# DDRSS0_CTL_CFG register map
Vendor: Texas Instruments
Registers are 32-bit, read-write, reset 0x0 unless marked. A register's access mark holds for its fields unless they carry their own. Offsets are as the file gives them; [hi:lo] are bit positions; lines under a group give offsets from that group.

## DDRSS0_CTL_CFG (part 2 of 5)
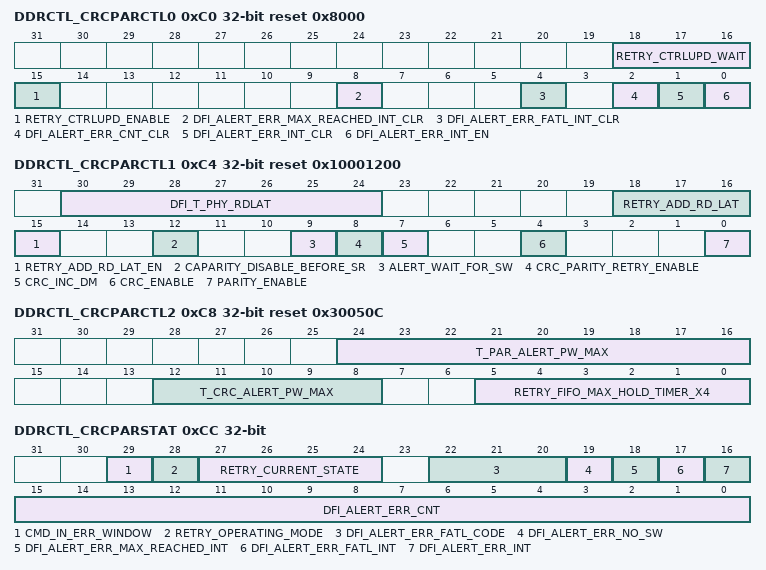
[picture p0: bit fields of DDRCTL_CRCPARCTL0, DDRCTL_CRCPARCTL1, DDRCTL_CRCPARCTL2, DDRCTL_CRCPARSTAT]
0xC0 DDRCTL_CRCPARCTL0 access not given reset 0x8000 — CRC Parity Control Register0
  [18:16] RETRY_CTRLUPD_WAIT rw — Additional wait time after dfi_ctrlupd_req for retry has occurred to ensure PHY's internals (FIFO pointers) have been reset correctly.Value used is 2^retry_ctrlupd_wait. Only used if DDRCTL_CRCPARCTL0.retry_ctrlupd_enable is enabled. Programming Mode: Static
  [15] RETRY_CTRLUPD_ENABLE rw — dfi_ctrlupd_req enable for retry.- 1: Enable to issue dfi_ctrlupd_req before starting retry sequence - 0: Disable to issue dfi_ctrlupd_req before starting retry sequence The DFI controller update can be used to reset PHY FIFO pointers. If both DDRCTL_CRCPARCTL0.retry_cfrlupd_enable and DDRCTL_CRCPARCTL1.alert_wait_for_sw are enabled, dfi_ctrlupd_req is issued just before software intervention time. If DDRCTL_CRCPARCTL0.retry_cfrlupd_enable is enabled, dfi_ctrlupd_req will be issued regardless of DDRCTL_DFIUPD0.dis_auto_ctrlupd. Programming Mode: Static
  [8] DFI_ALERT_ERR_MAX_REACHED_INT_CLR — Interrupt clear bit for DFI alert counter saturation.If this bit is set, the alert error interrupt on DDRCTL_CRCPARSTAT.dfi_alert_err_max_reached_int is cleared. When the clear operation is complete, the uMCTL2 automatically clears this bit. Programming Mode: Dynamic (access RW1C)
  [4] DFI_ALERT_ERR_FATL_INT_CLR — Interrupt clear bit for dfi_alert_err_fatl_int.If this bit is set, the alert error interrupt on DDRCTL_CRCPARSTAT.dfi_alert_err_fatl_int is cleared. When the clear operation is complete, the uMCTL2 automatically clears this bit. Programming Mode: Dynamic (access RW1C)
  [2] DFI_ALERT_ERR_CNT_CLR — DFI alert error count clear.Clear bit for DFI alert error counter. Asserting this bit will clear the DFI alert error counter, DDRCTL_CRCPARSTAT.dfi_alert_err_cnt. When the clear operation is complete, the uMCTL2 automatically clears this bit. Programming Mode: Dynamic (access RW1C)
  [1] DFI_ALERT_ERR_INT_CLR — Interrupt clear bit for DFI alert error.If this bit is set, the alert error interrupt on DDRCTL_CRCPARSTAT.dfi_alert_err_int will be cleared. When the clear operation is complete, the uMCTL2 automatically clears this bit. Programming Mode: Dynamic (access RW1C)
  [0] DFI_ALERT_ERR_INT_EN rw — Interrupt enable bit for DFI alert error.If this bit is set, any parity/CRC error detected on the dfi_alert_n input will result in an interrupt being set on DDRCTL_CRCPARSTAT.dfi_alert_err_int. Programming Mode: Dynamic
0xC4 DDRCTL_CRCPARCTL1 reset 0x10001200 — CRC Parity Control Register1
  [30:24] DFI_T_PHY_RDLAT — The maximum time allowed from the assertion of the dfi_rddata_en signal to the assertion of each of the corresponding bits of the dfi_rddata_valid signal.This corresponds to the DFI timing parameter tphy_rdlat. Refer to PHY specification for correct value. This value it only used for detecting read data timeout when DDR4 retry is enabled by DDRCTL_CRCPARCTL1.crc_parity_retry_enable=1. When the controller is operating in 1:2 frequency ratio mode, program this to the DFI timing parameter tphy_rdlat/2, and round it up to the next integer value. Unit: DFI clock cycles. Programming Mode: Static
  [18:16] RETRY_ADD_RD_LAT — Retry additional read latency value.Delay value used is retry_add_rd_lat+1. Only used if DDRCTL_CRCPARCTL1.retry_add_rd_lat_en is enabled. Selects the number of pipeline stages to dfi_rddata_valid/dfi_rddata/dfi_rddata_dbi before rest of internal uMCTL2 logic observes it. Required to compensate for fact delay in PHY/PCB for generating dfi_alert_n for retry may be more than the delay in PHY/PCB on read data path. Recommended settings (in terms of core_ddrc_core_clk): (Maximum Alert delay through PHY/PCB from erroneous read command including tPAR_UNKNOWN) - (Minimum Read data delay through PHY/PCB from erroneous read command) + (PHY's max granularity of dfi_rddata beats that may be corrupted before erroneous Read) Note: This calculation depends on various items such as RL, tPAR_ALERT_ON/tPAR_UNKNOWN/RCD/PHY/PCB behavior. Unit: DFI clock cycles. Programming Mode: Static
  [15] RETRY_ADD_RD_LAT_EN — Retry additional read latency enable.Number of pipeline stages selected is defined as DDRCTL_CRCPARCTL1.retry_add_lat+1. Only set if DDRCTL_CRCPARCTL1.crc_parity_retry_enable = 1 Programming Mode: Static
  [12] CAPARITY_DISABLE_BEFORE_SR — If DDR4-SDRAM's CA parity is enabled by DDRCTL_INIT6.mr5[2:0]!=0 and this register is set to 1, CA parity is automatically disabled before Self-Refresh entry and enabled after Self-Refresh exit by issuing MR5. - 1: CA parity is disabled before Self-Refresh entry - 0: CA parity is not disabled before Self-Refresh entry If Geardown is used by DDRCTL_MSTR.geardown_mode=1, this register must be set to 1. If this register set to 0, DDRCTL_DRAMTMG5.t_ckesr and DDRCTL_DRAMTMG5.t_cksre must be increased by PL(Parity latency) Programming Mode: Static
  [9] ALERT_WAIT_FOR_SW — After a Parity or CRC error is flagged on dfi_alert_n signal, the software has an option to read the mode registers in the DRAM before the hardware begins the retry process -1: Wait for software to read/write the mode registers before hardware begins the retry. After software is done with its operations, it will clear the alert interrupt register bit - 0: Hardware can begin the retry right away after the dfi_alert_n pulse goes away. The value on this register is valid only when retry is enabled (CRCPARCTRL.crc_parity_retry_enable = 1) If this register is set to 1 and if the software doesn't clear the interrupt register after handling the parity/CRC error, then the hardware will not begin the retry process and the system will hang. In the case of Parity/CRC error, there are two possibilities when the software doesn't reset MR5[4] to 0. - (i) If 'Persistent parity' mode register bit is NOT set: the commands sent during retry and normal operation are executed without parity checking. The value in the Parity error log register MPR Page 1 is valid. - (ii) If 'Persistent parity' mode register bit is SET: Parity checking is done for commands sent during retry and normal operation. If multiple errors occur before MR5[4] is cleared, the error log in MPR Page 1 should be treated as 'Don't care'. Programming Mode: Static
  [8] CRC_PARITY_RETRY_ENABLE — -1: Enable command retry mechanism in case of C/A Parity or CRC error - 0: Disable command retry mechanism when C/A Parity or CRC features are enabled. Note that retry functionality is not supported if burst chop is enabled (DDRCTL_MSTR.burstchop = 1) and/or disable auto-refresh is enabled (DDRCTL_RFSHCTL3.dis_auto_refresh = 1) Programming Mode: Static
  [7] CRC_INC_DM — CRC Calculation setting register -1: CRC includes DM signal - 0: CRC not includes DM signal Present only in designs configured to support DDR4. Programming Mode: Static
  [4] CRC_ENABLE — CRC enable Register -1: Enable generation of CRC - 0: Disable generation of CRC The setting of this register should match the CRC mode register setting in the DRAM. Programming Mode: Static
  [0] PARITY_ENABLE — C/A Parity enable register -1: Enable generation of C/A parity and detection of C/A parity error - 0: Disable generation of C/A parity and disable detection of C/A parity error If RCD's parity error detection or SDRAM's parity detection is enabled, this register should be 1. Programming Mode: Static
0xC8 DDRCTL_CRCPARCTL2 reset 0x30050C — CRC Parity Control Register2
  [24:16] T_PAR_ALERT_PW_MAX — Value from the DRAM spec indicating the maximum width of the dfi_alert_n pulse when a parity error occurs.Recommended values: - tPAR_ALERT_PW.MAX When the controller is operating in 1:2 frequency ratio mode, program this to tPAR_ALERT_PW.MAX/2 and round up to next integer value. Values of 0, 1 and 2 are illegal. This value must be greater than DDRCTL_CRCPARCTL2.t_crc_alert_pw_max. Programming Mode: Static
  [12:8] T_CRC_ALERT_PW_MAX — Value from the DRAM spec indicating the maximum width of the dfi_alert_n pulse when a CRC error occurs.Recommended values: - tCRC_ALERT_PW.MAX When the controller is operating in 1:2 frequency ratio mode, program this to tCRC_ALERT_PW.MAX/2 and round up to next integer value. Values of 0, 1 and 2 are illegal. This value must be less than DDRCTL_CRCPARCTL2.t_par_alert_pw_max. Programming Mode: Static
  [5:0] RETRY_FIFO_MAX_HOLD_TIMER_X4 — Indicates the maximum duration in number of DRAM clock cycles for which a command should be held in the Command Retry FIFO before it is popped out.Every location in the Command Retry FIFO has an associated down counting timer that will use this register as the start value. The down counting starts when a command is loaded into the FIFO. The timer counts down every 4 DRAM cycles. When the counter reaches zero, the entry is popped from the FIFO. All the counters are frozen, if a C/A Parity or CRC error occurs before the counter reaches zero. The counter is reset to 0, after all the commands in the FIFO are retried. Recommended(minimum) values: - Only C/A Parity is enabled. RoundUp((PHY Command Latency(DRAM CLK) + CAL + RCD delay + tPAR_ALERT_ON.max + tPAR_UNKNOWN + PHY Alert Latency(DRAM CLK) + board delay + PHY's max granularity of dfi_rddata beats that may be corrupted before erroneous Read) / 4) + 2 - Only CRC is enabled. RoundUp((PHY Command Latency(DRAM CLK) + CAL + RCD delay + WL + 5(BL10)+ tCRC_ALERT.max + PHY Alert Latency(DRAM CLK) + board delay) / 4) + 2 - If both C/A Parity and CRC are enabled. Use max of (Only C/A Parity is enabled, Only CRC is enabled) Note 1: All value (e.g. tPAR_ALERT_ON) should be in terms of DRAM Clock and round up Note 2: Board delay(Command/Alert_n) should be considered. Note 3: Use the worst case(longer) value for PHY Latencies/Board delay Note 4: The Recommended values are minimum value to be set. Note 5: RCD delay above refers to RDIMMs and LRDIMMs. Note 6: PHY's max granularity of dfi_rddata beats that may be corrupted before erroneous Read is depends on the internal architecture of the PHY. Max value can be set to this register is defined below: - MEMC_BURST_LENGTH == 16 Full bus Mode (CRC=OFF) Max value = UMCTL2_RETRY_CMD_FIFO_DEPTH - 2 Full bus Mode (CRC=ON) Max value = UMCTL2_RETRY_CMD_FIFO_DEPTH - 3 Half bus Mode (CRC=OFF) Max value = UMCTL2_RETRY_CMD_FIFO_DEPTH - 4 Half bus Mode (CRC=ON) Max value = UMCTL2_RETRY_CMD_FIFO_DEPTH - 6 Quarter bus Mode (CRC=OFF) Max value = UMCTL2_RETRY_CMD_FIFO_DEPTH - 8 Quarter bus Mode (CRC=ON) Max value = UMCTL2_RETRY_CMD_FIFO_DEPTH - 12 - MEMC_BURST_LENGTH != 16 Full bus Mode (CRC=OFF) Max value = UMCTL2_RETRY_CMD_FIFO_DEPTH - 1 Full bus Mode (CRC=ON) Max value = UMCTL2_RETRY_CMD_FIFO_DEPTH - 2 Half bus Mode (CRC=OFF) Max value = UMCTL2_RETRY_CMD_FIFO_DEPTH - 2 Half bus Mode (CRC=ON) Max value = UMCTL2_RETRY_CMD_FIFO_DEPTH - 3 Quarter bus Mode (CRC=OFF) Max value = UMCTL2_RETRY_CMD_FIFO_DEPTH - 4 Quarter bus Mode (CRC=ON) Max value = UMCTL2_RETRY_CMD_FIFO_DEPTH - 6 Values of 0, 1 and 2 are illegal. Programming Mode: Static
0xCC DDRCTL_CRCPARSTAT ro — CRC Parity Status Register
  [29] CMD_IN_ERR_WINDOW — Indicate if commands are in the parity/crc error window.- 0 - No command is in the parity/crc error window. - 1 - One or more commands are in the parity/crc error window or retry is in progress. This register is valid when CRCPARCTRL1.crc_parity_retry_enable=1. Programming Mode: Static
  [28] RETRY_OPERATING_MODE — Operating mode of retry -0 - Normal - 1 - Retry due to CRC/Parity error is in progress Programming Mode: Static
  [27:24] RETRY_CURRENT_STATE — Indicate current retry state for debug purposes only -0000 - IDLE:Retry is not enabled - 0001 - MON_DFI:Retry is enabled and monitoring DFI - 0010 - DETECTED ALERT:Detected dfi_alert_n - 0011 - WAKE_UP:Waking up from self-refresh state - 0100 - PRECHRGING:Pre-charging banks - 0101 - SEND_REF1:Sending extra REFs before software intervention time - 0110 - CTRLUPD:Issuing control update from retry logic - 0111 - WAIT_SW:Software intervention time - 1000 - SEND_REF2:Sending extra REFs before retrying commands - 1001 - RETRY_COMMANDS:Retrying commands - 1010 - RESTART_RETRY:Restarting retry due to alert_n detection during retry - 1111 - FATL_ERR:Fatal error detected FOR DEBUG PURPOSE ONLY Programming Mode: Static
  [22:20] DFI_ALERT_ERR_FATL_CODE — Indicate reason of dfi_alert_err_fatl_int assertion - [22] MPSMX caused parity error.(RCD's parity error detection only) - [21] Parity error happens again during software intervention time - [20] MRS was in retry_fifo_max_hold_timer_x4 window from alert_n=0 or DDRCTL_STAT.operating_mode is Init. Two or more reason can be available at the same time It remains set until cleared by DDRCTL_CRCPARCTL0.dfi_alert_err_fatl_clr. Programming Mode: Static
  [19] DFI_ALERT_ERR_NO_SW — Indicate whether software can perform MRS/MPR/PDA during software intervention time.- 0 - MRS/MPR/PDA can be performed during software intervention time - 1 - MRS/MPR/PDA can NOT be performed during software intervention time If DDRCTL_CRCPARCTL1.alert_wait_for_sw=1 and dfi_alert_err_no_sw=1, software can not perform MRS/MPR/PDA until dfi_alert_err_int is cleared by dfi_alert_err_int_clr. It remains set until cleared by DDRCTL_CRCPARCTL0.dfi_alert_err_int_clr. Programming Mode: Static
  [18] DFI_ALERT_ERR_MAX_REACHED_INT — DFI alert error counter max reached interrupt.If the DDRCTL_CRCPARSTAT.dfi_alert_err_cnt reaches it maximum value, this interrupt bit is set. It remains set until cleared by DDRCTL_CRCPARCTL0.dfi_alert_err_int_clr Programming Mode: Static
  [17] DFI_ALERT_ERR_FATL_INT — Fatal parity error interrupt.One or more these situation below happens, this interrupt bit is set. - MPSMX caused parity error. (RCD's parity error detection only) - Parity error happens again during software intervention time - MRS was in retry_fifo_max_hold_timer_x4 window from alert_n=0 or DDRCTL_STAT.operating_mode is Init. It remains set until cleared by DDRCTL_CRCPARCTL0.dfi_alert_err_fatl_clr. If this interrupt is asserted, system reset is strongly recommended. Programming Mode: Static
  [16] DFI_ALERT_ERR_INT — DFI alert error interrupt.If a parity/CRC error is detected on dfi_alert_n, and the interrupt is enabled by DDRCTL_CRCPARCTL0.dfi_alert_err_int_en, this interrupt bit will be set. It will remain set until cleared by DDRCTL_CRCPARCTL0.dfi_alert_err_int_clr Programming Mode: Static
  [15:0] DFI_ALERT_ERR_CNT — DFI alert error count.If a parity/CRC error is detected on dfi_alert_n, this counter be incremented. This is independent of the setting of DDRCTL_CRCPARCTL0.dfi_alert_err_int_en. It will saturate at 0xFFFF, and can be cleared by asserting DDRCTL_CRCPARCTL0.dfi_alert_err_cnt_clr. Programming Mode: Static
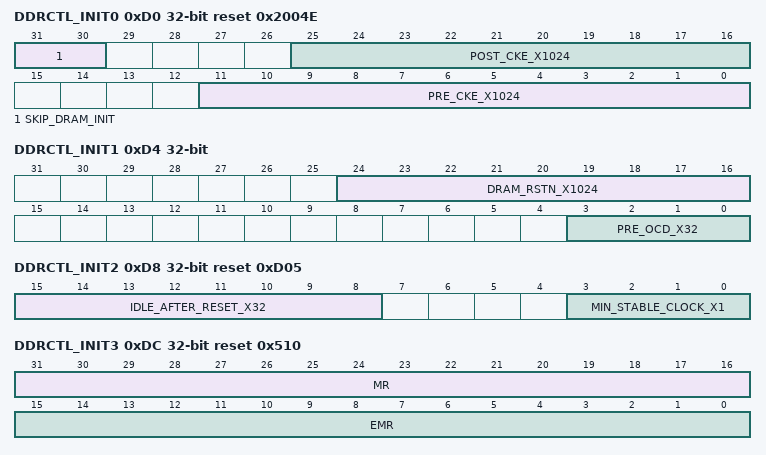
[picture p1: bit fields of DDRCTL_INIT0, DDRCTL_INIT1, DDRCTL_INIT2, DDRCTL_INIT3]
0xD0 DDRCTL_INIT0 reset 0x2004E — SDRAM Initialization Register 0
  [31:30] SKIP_DRAM_INIT — If lower bit is enabled the SDRAM initialization routine is skipped.The upper bit decides what state the controller starts up in when reset is removed - 00 - SDRAM Intialization routine is run after power-up - 01 - SDRAM Intialization routine is skipped after power-up. Controller starts up in Normal Mode - 11 - SDRAM Intialization routine is skipped after power-up. Controller starts up in Self-refresh Mode - 10 - SDRAM Intialization routine is run after power-up. Programming Mode: Quasi-dynamic Group 2
  [25:16] POST_CKE_X1024 — Cycles to wait after driving CKE high to start the SDRAM initialization sequence.Unit: 1024 DFI clock cycles. DDR2 typically requires a 400 ns delay, requiring this value to be programmed to 2 at all clock speeds. LPDDR2/LPDDR3 typically requires this to be programmed for a delay of 200 us. LPDDR4 typically requires this to be programmed for a delay of 2 us. When the controller is operating in 1:2 frequency ratio mode, program this to JEDEC spec value divided by 2, and round it up to the next integer value. Programming Mode: Static
  [11:0] PRE_CKE_X1024 — Cycles to wait after reset before driving CKE high to start the SDRAM initialization sequence.Unit: 1024 DFI clock cycles. DDR2 specifications typically require this to be programmed for a delay of &gt;= 200 us. LPDDR2/LPDDR3: tINIT1 of 100 ns (min) LPDDR4: tINIT3 of 2 ms (min) When the controller is operating in 1:2 frequency ratio mode, program this to JEDEC spec value divided by 2, and round it up to the next integer value. For DDR3/DDR4 RDIMMs, this should include the time needed to satisfy tSTAB Programming Mode: Static
0xD4 DDRCTL_INIT1 — SDRAM Initialization Register 1
  [24:16] DRAM_RSTN_X1024 — Number of cycles to assert SDRAM reset signal during init sequence.This is only present for designs supporting DDR3, DDR4 or LPDDR4 devices. For use with a DDR PHY, this should be set to a minimum of 1. When the controller is operating in 1:2 frequency ratio mode, program this to JEDEC spec value divided by 2, and round it up to the next integer value. Unit: 1024 DFI clock cycles. Programming Mode: Static
  [3:0] PRE_OCD_X32 — Wait period before driving the OCD complete command to SDRAM.Unit: Counts of a global timer that pulses every 32 DFI clock cycles. There is no known specific requirement for this it may be set to zero. Programming Mode: Static
0xD8 DDRCTL_INIT2 reset 0xD05 — SDRAM Initialization Register 2
  [15:8] IDLE_AFTER_RESET_X32 — Idle time after the reset command, tINIT4.Present only in designs configured to support LPDDR2. When the controller is operating in 1:2 frequency ratio mode, program this to JEDEC spec value divided by 2, and round it up to the next integer value. Unit: 32 DFI clock cycles. Programming Mode: Static
  [3:0] MIN_STABLE_CLOCK_X1 — Time to wait after the first CKE high, tINIT2.Present only in designs configured to support LPDDR2/LPDDR3. LPDDR2/LPDDR3 typically requires 5 x tCK delay. When the controller is operating in 1:2 frequency ratio mode, program this to JEDEC spec value divided by 2, and round it up to the next integer value. Unit: DFI clock cycles. Programming Mode: Static
0xDC DDRCTL_INIT3 reset 0x510 — SDRAM Initialization Register 3
  [31:16] MR — DDR2: Value to write to MR register. Bit 8 is for DLL and the setting here is ignored. The uMCTL2 sets this bit appropriately. DDR3/DDR4: Value loaded into MR0 register. mDDR: Value to write to MR register. LPDDR2/LPDDR3/LPDDR4 - Value to write to MR1 register Programming Mode: Quasi-dynamic Group 1 and Group 4
  [15:0] EMR — DDR2: Value to write to EMR register. Bits 9:7 are for OCD and the setting in this register is ignored. The uMCTL2 sets those bits appropriately. DDR3/DDR4: Value to write to MR1 register Set bit 7 to 0. If PHY-evaluation mode training is enabled, this bit is set appropriately by the uMCTL2 during write leveling. mDDR: Value to write to EMR register. LPDDR2/LPDDR3/LPDDR4 - Value to write to MR2 register Programming Mode: Quasi-dynamic Group 4
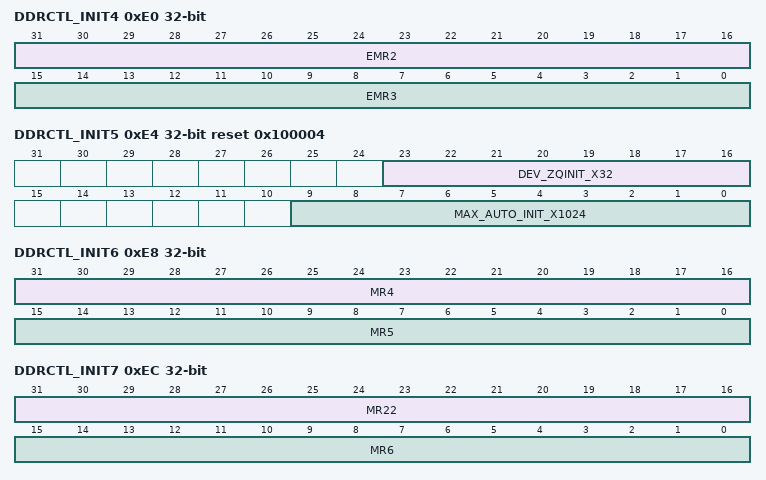
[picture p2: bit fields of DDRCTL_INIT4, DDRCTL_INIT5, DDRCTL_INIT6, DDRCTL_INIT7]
0xE0 DDRCTL_INIT4 — SDRAM Initialization Register 4
  [31:16] EMR2 — DDR2: Value to write to EMR2 register. DDR3/DDR4: Value to write to MR2 register LPDDR2/LPDDR3/LPDDR4: Value to write to MR3 register mDDR: Unused Programming Mode: Quasi-dynamic Group 4
  [15:0] EMR3 — DDR2: Value to write to EMR3 register. DDR3/DDR4: Value to write to MR3 register mDDR/LPDDR2/LPDDR3: Unused LPDDR4: Value to write to MR13 register Programming Mode: Quasi-dynamic Group 2 and Group 4
0xE4 DDRCTL_INIT5 reset 0x100004 — SDRAM Initialization Register 5
  [23:16] DEV_ZQINIT_X32 — ZQ initial calibration, tZQINIT.Present only in designs configured to support DDR3 or DDR4 or LPDDR2/LPDDR3. DDR3 typically requires 512 SDRAM clock cycles. DDR4 requires 1024 SDRAM clock cycles. LPDDR2/LPDDR3 requires 1 us. When the controller is operating in 1:2 frequency ratio mode, program this to JEDEC spec value divided by 2, and round it up to the next integer value. Unit: 32 DFI clock cycles. Programming Mode: Static
  [9:0] MAX_AUTO_INIT_X1024 — Maximum duration of the auto initialization, tINIT5.Present only in designs configured to support LPDDR2/LPDDR3. LPDDR2/LPDDR3 typically requires 10 us. Unit: 1024 DFI clock cycles. Programming Mode: Static
0xE8 DDRCTL_INIT6 — SDRAM Initialization Register 6
  [31:16] MR4 — DDR4- Value to be loaded into SDRAM MR4 registers. LPDDR4- Value to be loaded into SDRAM MR11 registers. Programming Mode: Quasi-dynamic Group 2 and Group 4
  [15:0] MR5 — DDR4- Value to be loaded into SDRAM MR5 registers. LPDDR4- Value to be loaded into SDRAM MR12 registers. Programming Mode: Quasi-dynamic Group 1 and Group 4
0xEC DDRCTL_INIT7 — SDRAM Initialization Register 7
  [31:16] MR22 — LPDDR4- Value to be loaded into SDRAM MR22 registers. Used in LPDDR4 designs only. Programming Mode: Quasi-dynamic Group 4
  [15:0] MR6 — DDR4- Value to be loaded into SDRAM MR6 registers. LPDDR4- Value to be loaded into SDRAM MR14 registers. Programming Mode: Quasi-dynamic Group 4
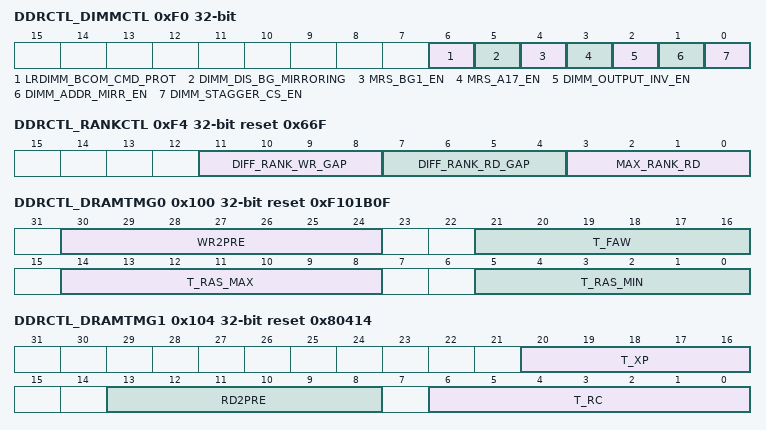
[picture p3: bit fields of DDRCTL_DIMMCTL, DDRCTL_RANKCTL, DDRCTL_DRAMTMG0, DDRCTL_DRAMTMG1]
0xF0 DDRCTL_DIMMCTL — DIMM Control Register
  [6] LRDIMM_BCOM_CMD_PROT — Protects the timing restrictions (tBCW/tMRC) between consecutive BCOM commands defined in the Data Buffer specification.When using DDR4 LRDIMM, this bit must be set to 1. Otherwise, this bit must be set to 0. Programming Mode: Static
  [5] DIMM_DIS_BG_MIRRORING — Disabling Address Mirroring for BG bits.When this is set to 1, BG0 and BG1 are NOT swapped even if Address Mirroring is enabled. This will be required for DDR4 DIMMs with x16 devices. - 1 - BG0 and BG1 are NOT swapped. - 0 - BG0 and BG1 are swapped if address mirroring is enabled. Programming Mode: Static
  [4] MRS_BG1_EN — Enable for BG1 bit of MRS command.BG1 bit of the mode register address is specified as RFU (Reserved for Future Use) and must be programmed to 0 during MRS. In case where DRAMs which do not have BG1 are attached and both the CA parity and the Output Inversion are enabled, this must be set to 0, so that the calculation of CA parity will not include BG1 bit. Note: This has no effect on the address of any other memory accesses, or of software-driven mode register accesses. If address mirroring is enabled, this is applied to BG1 of even ranks and BG0 of odd ranks. - 1 - Enabled - 0 - Disabled Programming Mode: Static
  [3] MRS_A17_EN — Enable for A17 bit of MRS command.A17 bit of the mode register address is specified as RFU (Reserved for Future Use) and must be programmed to 0 during MRS. In case where DRAMs which do not have A17 are attached and the Output Inversion are enabled, this must be set to 0, so that the calculation of CA parity will not include A17 bit. Note: This has no effect on the address of any other memory accesses, or of software-driven mode register accesses. - 1 - Enabled - 0 - Disabled Programming Mode: Static
  [2] DIMM_OUTPUT_INV_EN — Output Inversion Enable (for DDR4 RDIMM/LRDIMM implementations only).DDR4 RDIMM/LRDIMM implements the Output Inversion feature by default, which means that the following address, bank address and bank group bits of B-side DRAMs are inverted: A3-A9, A11, A13, A17, BA0-BA1, BG0-BG1. Setting this bit ensures that, for mode register accesses generated by the uMCTL2 during the automatic initialization routine and enabling of a particular DDR4 feature, separate A-side and B-side mode register accesses are generated. For B-side mode register accesses, these bits are inverted within the uMCTL2 to compensate for this RDIMM/LRDIMM inversion. It is recommended to set this bit always, if using DDR4 RDIMMs/LRDIMMs. Note: This has no effect on the address of any other memory accesses, or of software-driven mode register accesses. - 1 - Implement output inversion for B-side DRAMs. - 0 - Do not implement output inversion for B-side DRAMs. Programming Mode: Static
  [1] DIMM_ADDR_MIRR_EN — Address Mirroring Enable (for multi-rank UDIMM implementations and multi-rank DDR4 RDIMM/LRDIMM implementations).Some UDIMMs and DDR4 RDIMMs/LRDIMMs implement address mirroring for odd ranks, which means that the following address, bank address and bank group bits are swapped: (A3, A4), (A5, A6), (A7, A8), (BA0, BA1) and also (A11, A13), (BG0, BG1) for the DDR4. Setting this bit ensures that, for mode register accesses during the automatic initialization routine, these bits are swapped within the uMCTL2 to compensate for this UDIMM/RDIMM/LRDIMM swapping. In addition to the automatic initialization routine, in case of DDR4 UDIMM/RDIMM/LRDIMM, they are swapped during the automatic MRS access to enable/disable of a particular DDR4 feature. Note: This has no effect on the address of any other memory accesses, or of software-driven mode register accesses. This is not supported for mDDR, LPDDR2, LPDDR3 or LPDDR4 SDRAMs. Note: In case of x16 DDR4 DIMMs, BG1 output of MRS for the odd ranks is same as BG0 because BG1 is invalid, hence dimm_dis_bg_mirroring register must be set to 1. - 1 - For odd ranks, implement address mirroring for MRS commands to during initialization and for any automatic DDR4 MRS commands (to be used if UDIMM/RDIMM/LRDIMM implements address mirroring) - 0 - Do not implement address mirroring Programming Mode: Static
  [0] DIMM_STAGGER_CS_EN — Staggering enable for multi-rank accesses (for multi-rank UDIMM, RDIMM and LRDIMM implementations only).This is not supported for mDDR, LPDDR2, LPDDR3 or LPDDR4 SDRAMs. Note: Even if this bit is set it does not take care of software driven MR commands (via DDRCTL_MRCTRL0/DDRCTL_MRCTRL1), where software is responsible to send them to seperate ranks as appropriate. - 1 - (DDR4) Send MRS commands to each ranks seperately - 1 - (non-DDR4) Send all commands to even and odd ranks seperately - 0 - Do not stagger accesses Programming Mode: Static
0xF4 DDRCTL_RANKCTL reset 0x66F — Rank Control Register
  [11:8] DIFF_RANK_WR_GAP — Only present for multi-rank configurations.Indicates the number of clocks of gap in data responses when performing consecutive writes to different ranks. This is used to switch the delays in the PHY to match the rank requirements. This value should consider both PHY requirement and ODT requirement. - PHY requirement: tphy_wrcsgap If CRC feature is enabled, should be increased by 1. If write preamble is set to 2tCK(DDR4 only), should be increased by 1. If write postamble is set to 1.5tCK(LPDDR4 only), should be increased by 1. - ODT requirement: The value programmed in this register takes care of the ODT switch off timing requirement when switching ranks during writes. For LPDDR4, the requirement is ODTLoff - ODTLon - BL/2 + 1 When the controller is operating in 1:1 mode, program this to the larger of PHY requirement or ODT requirement. When the controller is operating in 1:2 mode, program this to the larger value divided by two and round it up to the next integer. Note that, if using DDR4-LRDIMM, refer to TWRWR timing requirements in JEDEC DDR4 Data Buffer (DDR4DB01) Specification. Programming Mode: Quasi-dynamic Group 2
  [7:4] DIFF_RANK_RD_GAP — Only present for multi-rank configurations.Indicates the number of clocks of gap in data responses when performing consecutive reads to different ranks. This is used to switch the delays in the PHY to match the rank requirements. This value should consider both PHY requirement and ODT requirement. - PHY requirement: tphy_rdcsgap If read preamble is set to 2tCK(DDR4 only), should be increased by 1. If read postamble is set to 1.5tCK(LPDDR4 only), should be increased by 1. - ODT requirement: The value programmed in this register takes care of the ODT switch off timing requirement when switching ranks during reads. When the controller is operating in 1:1 mode, program this to the larger of PHY requirement or ODT requirement. When the controller is operating in 1:2 mode, program this to the larger value divided by two and round it up to the next integer. Note that, if using DDR4-LRDIMM, refer to TRDRD timing requirements in JEDEC DDR4 Data Buffer (DDR4DB01) Specification. Programming Mode: Static
  [3:0] MAX_RANK_RD — Only present for multi-rank configurations.Background: Reads to the same rank can be performed back-to-back. Reads to different ranks require additional gap dictated by the register DDRCTL_RANKCTL.diff_rank_rd_gap. This is to avoid possible data bus contention as well as to give PHY enough time to switch the delay when changing ranks. The uMCTL2 arbitrates for bus access on a cycle-by-cycle basis therefore after a read is scheduled, there are few clock cycles (determined by the value on DDRCTL_RANKCTL.diff_rank_rd_gap register) in which only reads from the same rank are eligible to be scheduled. This prevents reads from other ranks from having fair access to the data bus. This parameter represents the maximum number of reads that can be scheduled consecutively to the same rank. After this number is reached, a delay equal to DDRCTL_RANKCTL.diff_rank_rd_gap is inserted by the scheduler to allow all ranks a fair opportunity to be scheduled. Higher numbers increase bandwidth utilization, lower numbers increase fairness. This feature can be DISABLED by setting this register to 0. When set to 0, the Controller will stay on the same rank as long as commands are available for it. Minimum programmable value is 0 (feature disabled) and maximum programmable value is 0xF. FOR PERFORMANCE ONLY. Programming Mode: Static
0x100 DDRCTL_DRAMTMG0 reset 0xF101B0F — SDRAM Timing Register 0
  [30:24] WR2PRE — Minimum time between write and precharge to same bank.Unit: Clocks Specifications: WL + BL/2 + tWR = approximately 8 cycles + 15 ns = 14 clocks MHz and less for lower frequencies where: - WL = write latency - BL = burst length. This must match the value programmed in the BL bit of the mode register to the SDRAM. BST (burst terminate) is not supported at present. - tWR = Write recovery time. This comes directly from the SDRAM specification. Add one extra cycle for LPDDR2/LPDDR3/LPDDR4 for this parameter. When the controller is operating in 1:2 frequency ratio mode, 1T mode, divide the above value by 2. No rounding up. When the controller is operating in 1:2 frequency ratio mode, 2T mode or LPDDR4 mode, divide the above value by 2 and round it up to the next integer value. Note that, depending on the PHY, if using LRDIMM, it may be necessary to adjust the value of this parameter to compensate for the extra cycle of latency through the LRDIMM. Programming Mode: Quasi-dynamic Group 1 and Group 2 and Group 4
  [21:16] T_FAW — tFAW Valid only when 8 or more banks(or banks x bank groups) are present.In 8-bank design, at most 4 banks must be activated in a rolling window of tFAW cycles. When the controller is operating in 1:2 frequency ratio mode, program this to (tFAW/2) and round up to next integer value. In a 4-bank design, set this register to 0x1 independent of the 1:1/1:2 frequency mode. Unit: Clocks Programming Mode: Quasi-dynamic Group 2 and Group 4
  [14:8] T_RAS_MAX — tRAS(max): Maximum time between activate and precharge to same bank.This is the maximum time that a page can be kept open Minimum value of this register is 1. Zero is invalid. When the controller is operating in 1:2 frequency ratio mode, program this to (tRAS(max)-1)/2. No rounding up. Unit: Multiples of 1024 clocks. Programming Mode: Quasi-dynamic Group 2 and Group 4
  [5:0] T_RAS_MIN — tRAS(min): Minimum time between activate and precharge to the same bank.When the controller is operating in 1:2 frequency mode, 1T mode, program this to tRAS(min)/2. No rounding up. When the controller is operating in 1:2 frequency ratio mode, 2T mode or LPDDR4 mode, program this to (tRAS(min)/2) and round it up to the next integer value. Unit: Clocks Programming Mode: Quasi-dynamic Group 2 and Group 4
0x104 DDRCTL_DRAMTMG1 reset 0x80414 — SDRAM Timing Register 1
  [20:16] T_XP — tXP: Minimum time after power-down exit to any operation.For DDR3, this should be programmed to tXPDLL if slow powerdown exit is selected in MR0[12]. If C/A parity for DDR4 is used, set to (tXP+PL) instead. If LPDDR4 is selected and its spec has tCKELPD parameter, set to the larger of tXP and tCKELPD instead. When the controller is operating in 1:2 frequency ratio mode, program this to (tXP/2) and round it up to the next integer value. Units: Clocks Programming Mode: Quasi-dynamic Group 2 and Group 4
  [13:8] RD2PRE — tRTP: Minimum time from read to precharge of same bank.- DDR2: tAL + BL/2 + max(tRTP, 2) - 2 - DDR3: tAL + max (tRTP, 4) - DDR4: Max of following two equations: tAL + max (tRTP, 4) or, RL + BL/2 - tRP (*). - mDDR: BL/2 - LPDDR2: Depends on if it's LPDDR2-S2 or LPDDR2-S4: LPDDR2-S2: BL/2 + tRTP - 1. LPDDR2-S4: BL/2 + max(tRTP,2) - 2. - LPDDR3: BL/2 + max(tRTP,4) - 4 - LPDDR4: BL/2 + max(tRTP,8) - 8 (*) When both DDR4 SDRAM and ST-MRAM are used simultaneously, use SDRAM's tRP value for calculation. When the controller is operating in 1:2 mode, 1T mode, divide the above value by 2. No rounding up. When the controller is operating in 1:2 mode, 2T mode or LPDDR4 mode, divide the above value by 2 and round it up to the next integer value. Unit: Clocks. Programming Mode: Quasi-dynamic Group 1 and Group 2 and Group 4
  [6:0] T_RC — tRC: Minimum time between activates to same bank.When the controller is operating in 1:2 frequency ratio mode, program this to (tRC/2) and round up to next integer value. Unit: Clocks. Programming Mode: Quasi-dynamic Group 2 and Group 4
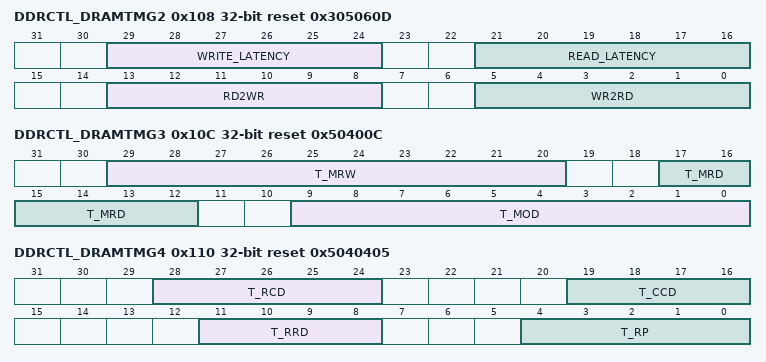
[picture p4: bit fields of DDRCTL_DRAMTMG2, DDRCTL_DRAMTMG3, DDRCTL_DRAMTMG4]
0x108 DDRCTL_DRAMTMG2 reset 0x305060D — SDRAM Timing Register 2
  [29:24] WRITE_LATENCY — Set to WL Time from write command to write data on SDRAM interface.This must be set to WL. For mDDR, it should normally be set to 1. Note that, depending on the PHY, if using RDIMM/LRDIMM, it may be necessary to adjust the value of WL to compensate for the extra cycle of latency through the RDIMM/LRDIMM. When the controller is operating in 1:2 frequency ratio mode, divide the value calculated using the above equation by 2, and round it up to next integer. This register field is not required for DDR2 and DDR3 (except if MEMC_TRAINING is set), as the DFI read and write latencies defined in DDRCTL_DFITMG0 and DDRCTL_DFITMG1 are sufficient for those protocols Unit: clocks Programming Mode: Quasi-dynamic Group 1 and Group 2 and Group 4
  [21:16] READ_LATENCY — Set to RL Time from read command to read data on SDRAM interface.This must be set to RL. Note that, depending on the PHY, if using RDIMM/LRDIMM, it may be necessary to adjust the value of RL to compensate for the extra cycle of latency through the RDIMM/LRDIMM. When the controller is operating in 1:2 frequency ratio mode, divide the value calculated using the above equation by 2, and round it up to next integer. This register field is not required for DDR2 and DDR3 (except if MEMC_TRAINING is set), as the DFI read and write latencies defined in DDRCTL_DFITMG0 and DDRCTL_DFITMG1 are sufficient for those protocols Unit: clocks Programming Mode: Quasi-dynamic Group 1 and Group 2 and Group 4
  [13:8] RD2WR — DDR2/3/mDDR: RL + BL/2 +2 - WL DDR4: RL + BL/2 + 1 + WR_PREAMBLE - WL LPDDR2/LPDDR3: RL + BL/2 + RU(tDQSCKmax/tCK) + 1 - WL LPDDR4(DQ ODT is Disabled): RL + BL/2 + RU(tDQSCKmax/tCK) + WR_PREAMBLE + RD_POSTAMBLE - WL LPDDR4(DQ ODT is Enabled) : RL + BL/2 + RU(tDQSCKmax/tCK) + RD_POSTAMBLE - ODTLon - RU(tODTon(min)/tCK) Minimum time from read command to write command. Include time for bus turnaround and all per-bank, per-rank, and global constraints. Unit: Clocks. Where: - WL = write latency - BL = burst length. This must match the value programmed in the BL bit of the mode register to the SDRAM - RL = read latency = CAS latency - WR_PREAMBLE = write preamble. This is unique to DDR4 and LPDDR4. - RD_POSTAMBLE = read postamble. This is unique to LPDDR4. For LPDDR2/LPDDR3/LPDDR4, if derating is enabled (DDRCTL_DERATEEN.derate_enable=1), derated tDQSCKmax should be used. When the controller is operating in 1:2 frequency ratio mode, divide the value calculated using the above equation by 2, and round it up to next integer. Note that, depending on the PHY, if using LRDIMM, it may be necessary to adjust the value of this parameter to compensate for the extra cycle of latency through the LRDIMM. Programming Mode: Quasi-dynamic Group 1 and Group 2 and Group 4
  [5:0] WR2RD — DDR4: CWL + PL + BL/2 + tWTR_L LPDDR2/3/4: WL + BL/2 + tWTR + 1 Others: CWL + BL/2 + tWTR In DDR4, minimum time from write command to read command for same bank group. In others, minimum time from write command to read command. Includes time for bus turnaround, recovery times, and all per-bank, per-rank, and global constraints. Unit: Clocks. Where: - CWL = CAS write latency - WL = Write latency - PL = Parity latency - BL = burst length. This must match the value programmed in the BL bit of the mode register to the SDRAM - tWTR_L = internal write to read command delay for same bank group. This comes directly from the SDRAM specification. - tWTR = internal write to read command delay. This comes directly from the SDRAM specification. Add one extra cycle for LPDDR2/LPDDR3/LPDDR4 operation. When the controller is operating in 1:2 mode, divide the value calculated using the above equation by 2, and round it up to next integer. Programming Mode: Quasi-dynamic Group 1 and Group 2 and Group 4
0x10C DDRCTL_DRAMTMG3 reset 0x50400C — SDRAM Timing Register 3
  [29:20] T_MRW — Time to wait after a mode register write or read (MRW or MRR).Present only in designs configured to support LPDDR2, LPDDR3 or LPDDR4. LPDDR2 typically requires value of 5. LPDDR3 typically requires value of 10. LPDDR4: Set this to the larger of tMRW and tMRWCKEL. For LPDDR2, this register is used for the time from a MRW/MRR to all other commands. When the controller is operating in 1:2 frequency ratio mode, program this to the above values divided by 2 and round it up to the next integer value. For LDPDR3, this register is used for the time from a MRW/MRR to a MRW/MRR. Programming Mode: Quasi-dynamic Group 2 and Group 4
  [17:12] T_MRD — tMRD: Cycles to wait after a mode register write or read.Depending on the connected SDRAM, tMRD represents: DDR2/mDDR: Time from MRS to any command DDR3/4: Time from MRS to MRS command LPDDR2: not used LPDDR3/4: Time from MRS to non-MRS command. When the controller is operating in 1:2 frequency ratio mode, program this to (tMRD/2) and round it up to the next integer value. If C/A parity for DDR4 is used, set to tMRD_PAR(tMOD+PL) instead. Programming Mode: Quasi-dynamic Group 2 and Group 4
  [9:0] T_MOD — tMOD: Parameter used only in DDR3 and DDR4.Cycles between load mode command and following non-load mode command. If C/A parity for DDR4 is used, set to tMOD_PAR(tMOD+PL) instead. If MPR writes for DDR4 are used, set to tMOD + AL (or tMPD_PAR + AL if C/A parity is also used). Set to tMOD if controller is operating in 1:1 frequency ratio mode, or tMOD/2 (rounded up to next integer) if controller is operating in 1:2 frequency ratio mode. Note that if using RDIMM/LRDIMM, depending on the PHY, it may be necessary to adjust the value of this parameter to compensate for the extra cycle of latency applied to mode register writes by the RDIMM/LRDIMM chip. Also note that if using LRDIMM, the minimum value of this register is tMRD_L2 if controller is operating in 1:1 frequency ratio mode, or tMRD_L2/2 (rounded up to next integer) if controller is operating in 1:2 frequency ratio mode. Programming Mode: Quasi-dynamic Group 2 and Group 4
0x110 DDRCTL_DRAMTMG4 reset 0x5040405 — SDRAM Timing Register 4
  [28:24] T_RCD — tRCD - tAL: Minimum time from activate to read or write command to same bank.When the controller is operating in 1:2 frequency ratio mode, program this to ((tRCD - tAL)/2) and round it up to the next integer value. Minimum value allowed for this register is 1, which implies minimum (tRCD - tAL) value to be 2 when the controller is operating in 1:2 frequency ratio mode. Unit: Clocks. Programming Mode: Quasi-dynamic Group 1 and Group 2 and Group 4
  [19:16] T_CCD — DDR4: tCCD_L: This is the minimum time between two reads or two writes for same bank group. Others: tCCD: This is the minimum time between two reads or two writes. When the controller is operating in 1:2 frequency ratio mode, program this to (tCCD_L/2 or tCCD/2) and round it up to the next integer value. Unit: clocks. Programming Mode: Quasi-dynamic Group 2 and Group 4
  [11:8] T_RRD — DDR4: tRRD_L: Minimum time between activates from bank 'a' to bank 'b' for same bank group. Others: tRRD: Minimum time between activates from bank 'a' to bank 'b' When the controller is operating in 1:2 frequency ratio mode, program this to (tRRD_L/2 or tRRD/2) and round it up to the next integer value. Unit: Clocks. Programming Mode: Quasi-dynamic Group 2 and Group 4
  [4:0] T_RP — tRP: Minimum time from precharge to activate of same bank.When the controller is operating in 1:1 frequency ratio mode, t_rp should be set to RoundUp(tRP/tCK). When the controller is operating in 1:2 frequency ratio mode, t_rp should be set to RoundDown(RoundUp(tRP/tCK)/2) + 1. When the controller is operating in 1:2 frequency ratio mode in LPDDR4, t_rp should be set to RoundUp(RoundUp(tRP/tCK)/2). Unit: Clocks. Programming Mode: Quasi-dynamic Group 2 and Group 4
